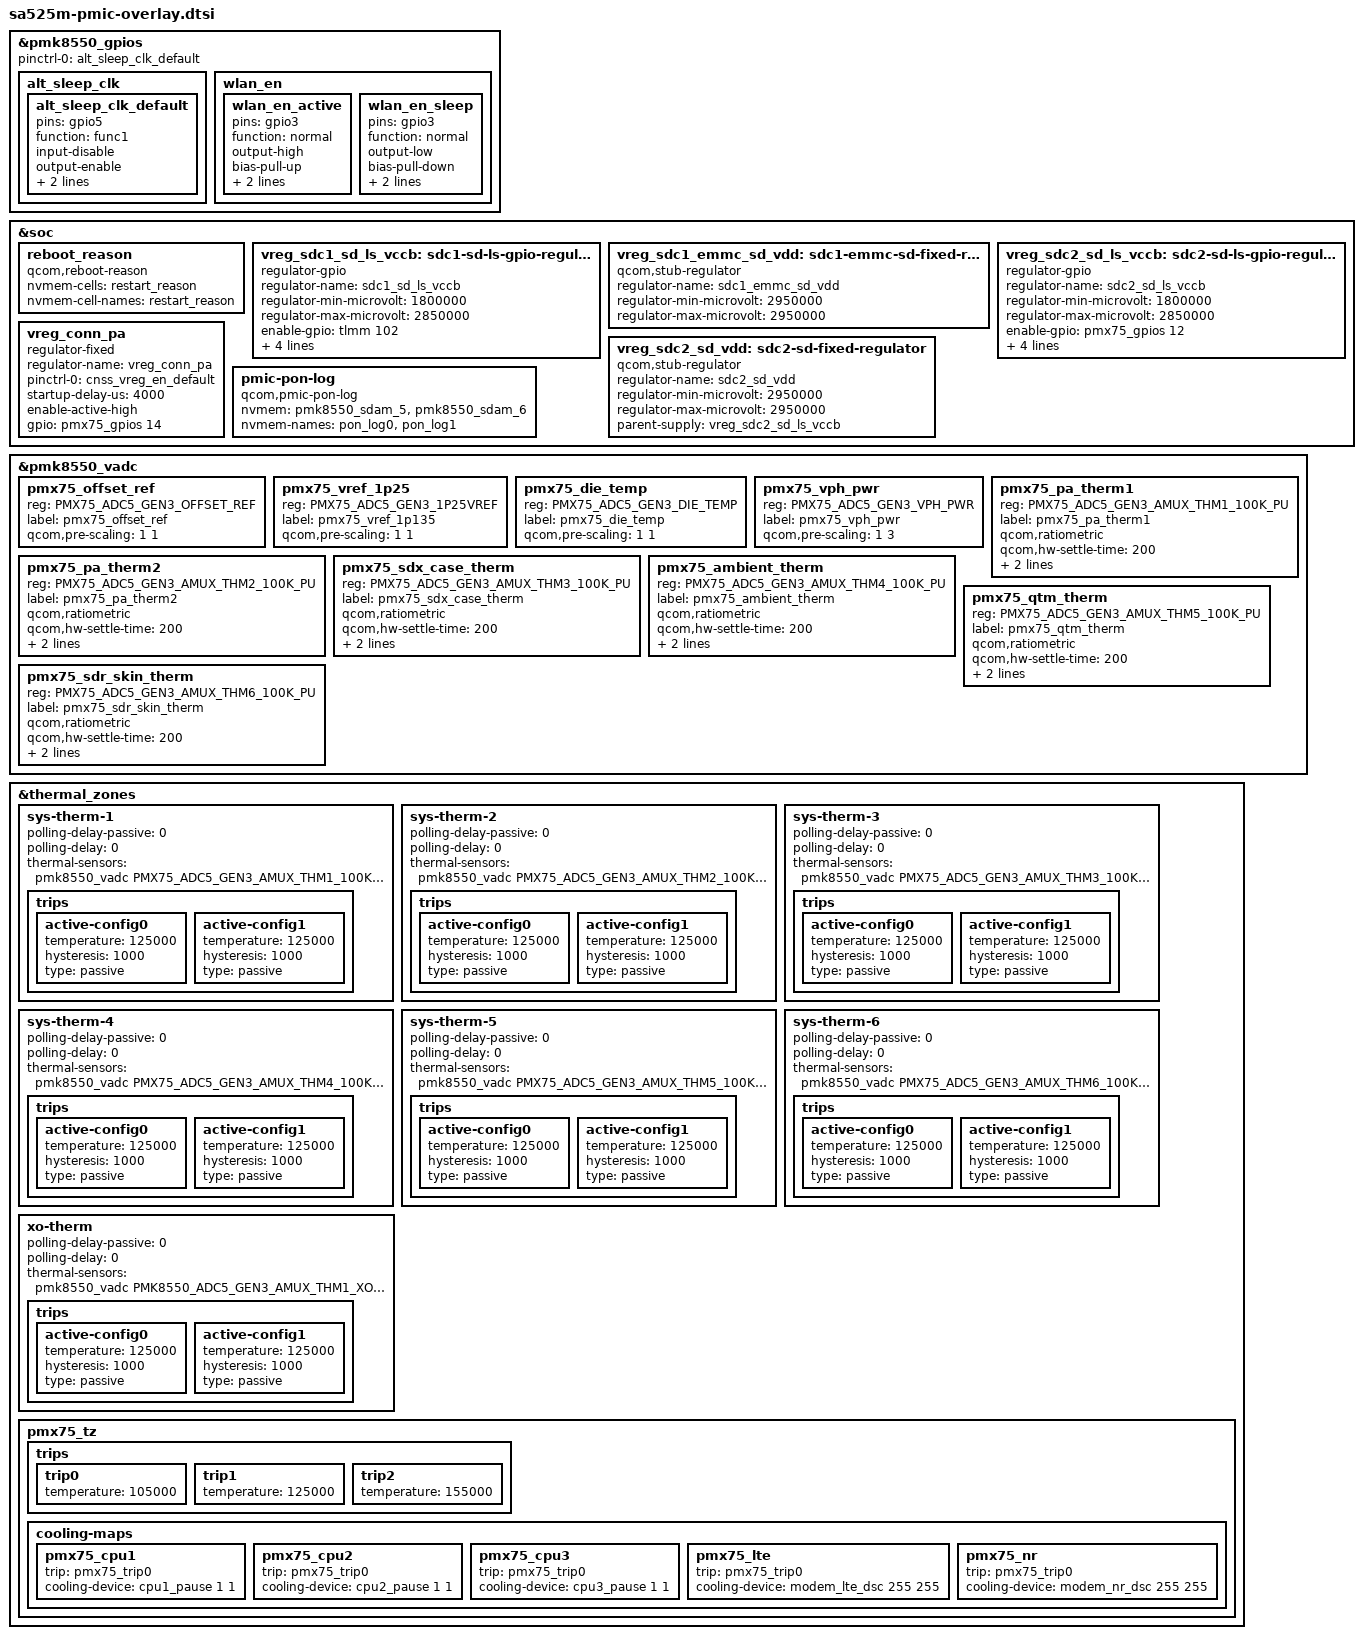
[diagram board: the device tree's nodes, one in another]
#include <dt-bindings/gpio/gpio.h>
#include <dt-bindings/iio/qcom,spmi-adc5-gen3-pmx75.h>

#include "pmk8550.dtsi"
#include "pmx75.dtsi"

&pmk8550_gpios {
	pinctrl-0 = <&alt_sleep_clk_default>;
	pinctrl-names = "default";

	alt_sleep_clk {
		alt_sleep_clk_default: alt_sleep_clk_default {
			pins = "gpio5";
			function = "func1";
			input-disable;
			output-enable;
			bias-disable;
			power-source = <0>;
		};
	};

	wlan_en {
		wlan_en_active: wlan_en_active {
			pins = "gpio3";
			function = "normal";
			output-high;
			bias-pull-up;
			qcom,drive-strength = <2>;
			power-source = <0>;
		};

		wlan_en_sleep: wlan_en_sleep {
			pins = "gpio3";
			function = "normal";
			output-low;
			bias-pull-down;
			qcom,drive-strength = <2>;
			power-source = <0>;
		};

	};
};

&soc {
	reboot_reason {
		compatible = "qcom,reboot-reason";
		nvmem-cells = <&restart_reason>;
		nvmem-cell-names = "restart_reason";
	};

	vreg_sdc1_sd_ls_vccb: sdc1-sd-ls-gpio-regulator {
		compatible = "regulator-gpio";
		regulator-name = "sdc1_sd_ls_vccb";
		regulator-min-microvolt = <1800000>;
		regulator-max-microvolt = <2850000>;
		enable-gpio = <&tlmm 102 GPIO_ACTIVE_HIGH>;
		gpios = <&tlmm 84 GPIO_ACTIVE_HIGH>;
		states = <1800000 0>,
			 <2850000 1>;
		startup-delay-us = <5000>;
		enable-active-high;
	};

	vreg_sdc1_emmc_sd_vdd: sdc1-emmc-sd-fixed-regulator {
		compatible = "qcom,stub-regulator";
		regulator-name = "sdc1_emmc_sd_vdd";
		regulator-min-microvolt = <2950000>;
		regulator-max-microvolt = <2950000>;
	};

	vreg_sdc2_sd_ls_vccb: sdc2-sd-ls-gpio-regulator {
		compatible = "regulator-gpio";
		regulator-name = "sdc2_sd_ls_vccb";
		regulator-min-microvolt = <1800000>;
		regulator-max-microvolt = <2850000>;
		enable-gpio = <&pmx75_gpios 12 GPIO_ACTIVE_HIGH>;
		gpios = <&tlmm 121 GPIO_ACTIVE_HIGH>;
		states = <1800000 0>,
			 <2850000 1>;
		startup-delay-us = <5000>;
		enable-active-high;
	};

	vreg_sdc2_sd_vdd: sdc2-sd-fixed-regulator {
		compatible = "qcom,stub-regulator";
		regulator-name = "sdc2_sd_vdd";
		regulator-min-microvolt = <2950000>;
		regulator-max-microvolt = <2950000>;
		parent-supply = <&vreg_sdc2_sd_ls_vccb>;
	};

	vreg_conn_pa: vreg_conn_pa {
		compatible = "regulator-fixed";
		regulator-name = "vreg_conn_pa";
		pinctrl-names = "default";
		pinctrl-0 = <&cnss_vreg_en_default>;
		startup-delay-us = <4000>;
		enable-active-high;
		gpio = <&pmx75_gpios 14 GPIO_ACTIVE_HIGH>;
	};

};

&pmk8550_vadc {
	/delete-node/ pm8550_offset_ref;
	/delete-node/ pm8550_vref_1p25;
	/delete-node/ pm8550_die_temp;
	/delete-node/ pm8550_vph_pwr;

	/delete-node/ pm8550b_offset_ref;
	/delete-node/ pm8550b_vref_1p25;
	/delete-node/ pm8550b_die_temp;
	/delete-node/ pm8550b_lite_die_temp;
	/delete-node/ pm8550b_vph_pwr;
	/delete-node/ pm8550b_vbat_sns_qbg;

	/delete-node/ pm8550vs_c_die_temp;
	/delete-node/ pm8550vs_d_die_temp;
	/delete-node/ pm8550vs_e_die_temp;
	/delete-node/ pm8550vs_g_die_temp;

	/delete-node/ pm8550ve_die_temp;

	/* PMX75 Channel nodes */
	pmx75_offset_ref {
		reg = <PMX75_ADC5_GEN3_OFFSET_REF>;
		label = "pmx75_offset_ref";
		qcom,pre-scaling = <1 1>;
	};

	pmx75_vref_1p25 {
		reg = <PMX75_ADC5_GEN3_1P25VREF>;
		label = "pmx75_vref_1p135";
		qcom,pre-scaling = <1 1>;
	};

	pmx75_die_temp {
		reg = <PMX75_ADC5_GEN3_DIE_TEMP>;
		label = "pmx75_die_temp";
		qcom,pre-scaling = <1 1>;
	};

	pmx75_vph_pwr {
		reg = <PMX75_ADC5_GEN3_VPH_PWR>;
		label = "pmx75_vph_pwr";
		qcom,pre-scaling = <1 3>;
	};

	pmx75_pa_therm1 {
		reg = <PMX75_ADC5_GEN3_AMUX_THM1_100K_PU>;
		label = "pmx75_pa_therm1";
		qcom,ratiometric;
		qcom,hw-settle-time = <200>;
		qcom,pre-scaling = <1 1>;
		qcom,adc-tm-type = <1>;
	};

	pmx75_pa_therm2 {
		reg = <PMX75_ADC5_GEN3_AMUX_THM2_100K_PU>;
		label = "pmx75_pa_therm2";
		qcom,ratiometric;
		qcom,hw-settle-time = <200>;
		qcom,pre-scaling = <1 1>;
		qcom,adc-tm-type = <1>;
	};

	pmx75_sdx_case_therm {
		reg = <PMX75_ADC5_GEN3_AMUX_THM3_100K_PU>;
		label = "pmx75_sdx_case_therm";
		qcom,ratiometric;
		qcom,hw-settle-time = <200>;
		qcom,pre-scaling = <1 1>;
		qcom,adc-tm-type = <1>;
	};

	pmx75_ambient_therm {
		reg = <PMX75_ADC5_GEN3_AMUX_THM4_100K_PU>;
		label = "pmx75_ambient_therm";
		qcom,ratiometric;
		qcom,hw-settle-time = <200>;
		qcom,pre-scaling = <1 1>;
		qcom,adc-tm-type = <1>;
	};

	pmx75_qtm_therm {
		reg = <PMX75_ADC5_GEN3_AMUX_THM5_100K_PU>;
		label = "pmx75_qtm_therm";
		qcom,ratiometric;
		qcom,hw-settle-time = <200>;
		qcom,pre-scaling = <1 1>;
		qcom,adc-tm-type = <1>;
	};

	pmx75_sdr_skin_therm {
		reg = <PMX75_ADC5_GEN3_AMUX_THM6_100K_PU>;
		label = "pmx75_sdr_skin_therm";
		qcom,ratiometric;
		qcom,hw-settle-time = <200>;
		qcom,pre-scaling = <1 1>;
		qcom,adc-tm-type = <1>;
	};
};

&thermal_zones {
	sys-therm-1 {
		polling-delay-passive = <0>;
		polling-delay = <0>;
		thermal-sensors = <&pmk8550_vadc PMX75_ADC5_GEN3_AMUX_THM1_100K_PU>;
		trips {
			active-config0 {
				temperature = <125000>;
				hysteresis = <1000>;
				type = "passive";
			};

			active-config1 {
				temperature = <125000>;
				hysteresis = <1000>;
				type = "passive";
			};
		};
	};

	sys-therm-2 {
		polling-delay-passive = <0>;
		polling-delay = <0>;
		thermal-sensors = <&pmk8550_vadc PMX75_ADC5_GEN3_AMUX_THM2_100K_PU>;
		trips {
			active-config0 {
				temperature = <125000>;
				hysteresis = <1000>;
				type = "passive";
			};

			active-config1 {
				temperature = <125000>;
				hysteresis = <1000>;
				type = "passive";
			};
		};
	};

	sys-therm-3 {
		polling-delay-passive = <0>;
		polling-delay = <0>;
		thermal-sensors = <&pmk8550_vadc PMX75_ADC5_GEN3_AMUX_THM3_100K_PU>;
		trips {
			active-config0 {
				temperature = <125000>;
				hysteresis = <1000>;
				type = "passive";
			};

			active-config1 {
				temperature = <125000>;
				hysteresis = <1000>;
				type = "passive";
			};
		};
	};

	sys-therm-4 {
		polling-delay-passive = <0>;
		polling-delay = <0>;
		thermal-sensors = <&pmk8550_vadc PMX75_ADC5_GEN3_AMUX_THM4_100K_PU>;
		trips {
			active-config0 {
				temperature = <125000>;
				hysteresis = <1000>;
				type = "passive";
			};

			active-config1 {
				temperature = <125000>;
				hysteresis = <1000>;
				type = "passive";
			};
		};
	};

	sys-therm-5 {
		polling-delay-passive = <0>;
		polling-delay = <0>;
		thermal-sensors = <&pmk8550_vadc PMX75_ADC5_GEN3_AMUX_THM5_100K_PU>;
		trips {
			active-config0 {
				temperature = <125000>;
				hysteresis = <1000>;
				type = "passive";
			};

			active-config1 {
				temperature = <125000>;
				hysteresis = <1000>;
				type = "passive";
			};
		};
	};

	sys-therm-6 {
		polling-delay-passive = <0>;
		polling-delay = <0>;
		thermal-sensors = <&pmk8550_vadc PMX75_ADC5_GEN3_AMUX_THM6_100K_PU>;
		trips {
			active-config0 {
				temperature = <125000>;
				hysteresis = <1000>;
				type = "passive";
			};

			active-config1 {
				temperature = <125000>;
				hysteresis = <1000>;
				type = "passive";
			};
		};
	};

	xo-therm {
		polling-delay-passive = <0>;
		polling-delay = <0>;
		thermal-sensors = <&pmk8550_vadc PMK8550_ADC5_GEN3_AMUX_THM1_XO_THERM_100K_PU>;
		trips {
			active-config0 {
				temperature = <125000>;
				hysteresis = <1000>;
				type = "passive";
			};

			active-config1 {
				temperature = <125000>;
				hysteresis = <1000>;
				type = "passive";
			};
		};
	};

	pmx75_tz {
		trips {
			trip0 {
				temperature = <105000>;
			};

			trip1 {
				temperature = <125000>;
			};

			trip2 {
				temperature = <155000>;
			};
		};

		cooling-maps {
			pmx75_cpu1 {
				trip = <&pmx75_trip0>;
				cooling-device = <&cpu1_pause 1 1>;
			};

			pmx75_cpu2 {
				trip = <&pmx75_trip0>;
				cooling-device = <&cpu2_pause 1 1>;
			};

			pmx75_cpu3 {
				trip = <&pmx75_trip0>;
				cooling-device = <&cpu3_pause 1 1>;
			};

			pmx75_lte {
				trip = <&pmx75_trip0>;
				cooling-device = <&modem_lte_dsc 255 255>;
			};

			pmx75_nr {
				trip = <&pmx75_trip0>;
				cooling-device = <&modem_nr_dsc 255 255>;
			};
		};
	};
};

&soc {
	pmic-pon-log {
		compatible = "qcom,pmic-pon-log";
		nvmem = <&pmk8550_sdam_5>, <&pmk8550_sdam_6>;
		nvmem-names = "pon_log0", "pon_log1";
	};
};
